# pss register map
Vendor: Texas Instruments
Peripheral module from a debugger description file (folder MSP432).
Registers are 32-bit, read-write, no defined reset value unless marked. A register's access mark holds for its fields unless they carry their own. Offsets are as the file gives them; lines under a group give offsets from that group; [hi:lo] are bit positions; {n}, {i} and the like mark numbered series; 'fields as' and 'values as' point back to an identical list; <NAME> marks a mode.

## PSS
0x00 KEY
  [15:0] KEY — PSS control key
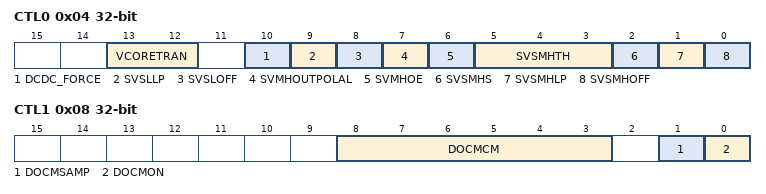
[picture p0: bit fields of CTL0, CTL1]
0x04 CTL0 — Control 0 Register
  [13:12] VCORETRAN — Controls VCORE Level Transition time
    0=VCORETRAN__0 (32 μs / 100 mV); 1=VCORETRAN__1 (64 μs / 100 mV); 2=VCORETRAN__2 (128 μs / 100 mV (default)); 3=VCORETRAN__3 (256 μs / 100 mV)
  [10] DCDC_FORCE — Disables automatic supply voltage detection and possible denial
    0=DCDC_FORCE__0 (Allow DC/DC power mode request to be denied if supply voltage i); 1=DCDC_FORCE__1 (Disable continuos monitor of supply voltage to see if DC/DC sho)
  [9] SVSLLP — SVS low-side low power normal performance mode
    0=SVSLLP__0 (Full performance mode); 1=SVSLLP__1 (Low power normal performance mode in LPM3, LPM4, and LPMx)
  [8] SVSLOFF — SVS low-side off
    0=SVSLOFF__0 (The SVSL is on); 1=SVSLOFF__1 (The SVSL is off)
  [7] SVMHOUTPOLAL — SVMHOUT pin polarity active low
    0=SVMHOUTPOLAL__0 (SVMHOUT is active high); 1=SVMHOUTPOLAL__1 (SVMHOUT is active low)
  [6] SVMHOE — SVSM high-side output enable
    0=SVMHOE__0 (SVSMHIFG bit is not output); 1=SVMHOE__1 (SVSMHIFG bit is output to the device SVMHOUT pin)
  [5:3] SVSMHTH — SVSM high-side reset voltage level
  [2] SVSMHS — Supply supervisor or monitor selection for the high-side
    0=SVSMHS__0 (Configure as SVSH); 1=SVSMHS__1 (Configure as SVMH)
  [1] SVSMHLP — SVSM high-side low power normal performance mode
    0=SVSMHLP__0 (Full performance mode); 1=SVSMHLP__1 (Low power normal performance mode in LPM3, LPM4, and LPMx)
  [0] SVSMHOFF — SVSM high-side off
    0=SVSMHOFF__0 (The SVSMH is on); 1=SVSMHOFF__1 (The SVSMH is off)
0x08 CTL1 — Control 1 Register
  [8:3] DOCMCM — Controls current mirrors in DOCM for conversion
  [1] DOCMSAMP — DOCM sample current
    0=DOCMSAMP__0 (Disable sampling switch inside LDO DOCM); 1=DOCMSAMP__1 (Enable sampling switch inside LDO DOCM)
  [0] DOCMON — Turns the DOCM module on or off
    0=DOCMON__0 (Disable DOCM); 1=DOCMON__1 (Enable DOCM)
0x0C CTL2 — Control 2 Register
  [5:0] DOCMOUT — DOCM comparator output
0x34 IE — Interrupt Enable Register
  [1] SVSMHIE — High-side SVSM interrupt enable, when set as a monitor (SVSMHS
    0=SVSMHIE__0 (Interrupt disabled); 1=SVSMHIE__1 (Interrupt enabled)
0x38 IFG — Interrupt Flag Register
  [1] SVSMHIFG — High-side SVSM interrupt flag
    0=SVSMHIFG__0 (No interrupt pending); 1=SVSMHIFG__1 (Interrupt due to SVSMH)
0x3C CLRIFG — Clear Interrupt Flag Register
  [1] CLRSVSMHIFG — SVSMH clear interrupt flag
    0=CLRSVSMHIFG__0 (No effect); 1=CLRSVSMHIFG__1 (Clear pending interrupt flag)
